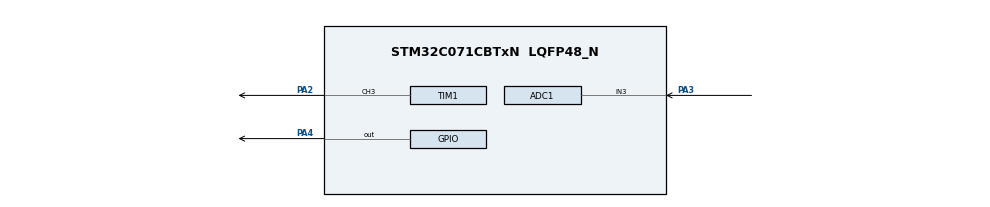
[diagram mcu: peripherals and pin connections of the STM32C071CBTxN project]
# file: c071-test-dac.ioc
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ADC1.DMAContinuousRequests=ENABLE
ADC1.ExternalTrigConv=ADC_EXTERNALTRIG_T1_TRGO2
ADC1.NbrOfConversionFlag=0
ADC1.Resolution=ADC_RESOLUTION_8B
ADC1.SelectedChannel=ADC_CHANNEL_3
ADC1.TriggerFrequencyMode=ADC_TRIGGER_FREQ_HIGH
ADC1.master=1
Dma.ADC1.0.Direction=DMA_PERIPH_TO_MEMORY
Dma.ADC1.0.EventEnable=DISABLE
Dma.ADC1.0.Instance=DMA1_Channel1
Dma.ADC1.0.MemDataAlignment=DMA_MDATAALIGN_BYTE
Dma.ADC1.0.MemInc=DMA_MINC_DISABLE
Dma.ADC1.0.Mode=DMA_CIRCULAR
Dma.ADC1.0.PeriphDataAlignment=DMA_PDATAALIGN_BYTE
Dma.ADC1.0.PeriphInc=DMA_PINC_DISABLE
Dma.ADC1.0.Polarity=HAL_DMAMUX_REQ_GEN_RISING
Dma.ADC1.0.Priority=DMA_PRIORITY_LOW
Dma.ADC1.0.RequestNumber=1
Dma.ADC1.0.SignalID=NONE
Dma.ADC1.0.SyncEnable=DISABLE
Dma.ADC1.0.SyncPolarity=HAL_DMAMUX_SYNC_NO_EVENT
Dma.ADC1.0.SyncRequestNumber=1
Dma.ADC1.0.SyncSignalID=NONE
Dma.Request0=ADC1
Dma.Request1=TIM1_CH3
Dma.TIM1_CH3.1.Direction=DMA_MEMORY_TO_PERIPH
Dma.TIM1_CH3.1.EventEnable=DISABLE
Dma.TIM1_CH3.1.Instance=DMA1_Channel2
Dma.TIM1_CH3.1.MemDataAlignment=DMA_MDATAALIGN_HALFWORD
Dma.TIM1_CH3.1.MemInc=DMA_MINC_DISABLE
Dma.TIM1_CH3.1.Mode=DMA_CIRCULAR
Dma.TIM1_CH3.1.PeriphDataAlignment=DMA_PDATAALIGN_HALFWORD
Dma.TIM1_CH3.1.PeriphInc=DMA_PINC_DISABLE
Dma.TIM1_CH3.1.Polarity=HAL_DMAMUX_REQ_GEN_RISING
Dma.TIM1_CH3.1.Priority=DMA_PRIORITY_MEDIUM
Dma.TIM1_CH3.1.RequestNumber=1
Dma.TIM1_CH3.1.SignalID=NONE
Dma.TIM1_CH3.1.SyncEnable=DISABLE
Dma.TIM1_CH3.1.SyncPolarity=HAL_DMAMUX_SYNC_NO_EVENT
Dma.TIM1_CH3.1.SyncRequestNumber=1
Dma.TIM1_CH3.1.SyncSignalID=NONE
Mcu.Family=STM32C0
Mcu.Name=STM32C071CBTxN
Mcu.Package=LQFP48_N
NVIC.DMA1_Channel2_3_IRQn=true\:0\:0\:false\:false\:true\:false\:true\:true
NVIC.TIM17_IRQn=true\:0\:0\:false\:false\:true\:true\:true\:true
PA13.Mode=Serial_Wire
PA13.Signal=DEBUG_SWDIO
PA14-BOOT0.Mode=Serial_Wire
PA14-BOOT0.Signal=DEBUG_SWCLK
PA2.Signal=S_TIM1_CH3
PA3.Mode=IN3
PA3.Signal=ADC1_IN3
PA4.Signal=GPIO_Output
ProjectManager.HeapSize=0x200
ProjectManager.StackSize=0x400
ProjectManager.TargetToolchain=STM32CubeIDE
RCC.ADCFreq_Value=48000000
RCC.AHBFreq_Value=48000000
RCC.CortexFreq_Value=48000000
RCC.EXTERNAL_CLOCK_VALUE=12288000
RCC.HCLKFreq_Value=48000000
RCC.HSE_VALUE=8000000
RCC.HSI48_VALUE=48000000
RCC.HSISYSCLKDivider=RCC_HSI_DIV1
RCC.HSI_VALUE=48000000
RCC.LSE_VALUE=32768
RCC.SYSCLKFreq_VALUE=48000000
SH.S_TIM1_CH3.0=TIM1_CH3,PWM Generation3 CH3
TIM1.Channel-PWM\ Generation3\ CH3=TIM_CHANNEL_3
TIM1.OC3Preload_PWM=ENABLE
TIM1.OCMode_PWM-PWM\ Generation3\ CH3=TIM_OCMODE_PWM1
TIM1.Period=255
TIM1.TIM_MasterOutputTrigger=TIM_TRGO_RESET
TIM1.TIM_MasterOutputTrigger2=TIM_TRGO2_UPDATE
TIM1.TIM_MasterSlaveMode=TIM_MASTERSLAVEMODE_ENABLE
TIM17.Period=1000
TIM17.Prescaler=47
VP_TIM17_VS_ClockSourceINT.Mode=Enable_Timer
VP_TIM1_VS_ClockSourceINT.Mode=Internal
board=custom

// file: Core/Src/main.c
/* USER CODE BEGIN Header */
/**
  ******************************************************************************
  * @file           : main.c
  * @brief          : Main program body
  ******************************************************************************
  * @attention
  *
  * Copyright (c) 2026 STMicroelectronics.
  * All rights reserved.
  *
  * This software is licensed under terms that can be found in the LICENSE file
  * in the root directory of this software component.
  * If no LICENSE file comes with this software, it is provided AS-IS.
  *
  ******************************************************************************
  */
/* USER CODE END Header */
#include "main.h"

ADC_HandleTypeDef hadc1;
DMA_HandleTypeDef hdma_adc1;

TIM_HandleTypeDef htim1;
TIM_HandleTypeDef htim17;
DMA_HandleTypeDef hdma_tim1_ch3;

/* USER CODE BEGIN PV */

uint16_t value = 0;
uint8_t maxSteps = 255;
uint8_t numSteps = 250;
float maxVoltage = 3.0;
float targetVoltage = 3.0;
uint8_t maxValue = 255;
uint8_t step = 1;
uint8_t endDelay = 1; //steps of delay

uint8_t adcValue = 0;
uint8_t adcValues[12][2];

/* USER CODE END PV */

void SystemClock_Config(void);
static void MX_GPIO_Init(void);
static void MX_DMA_Init(void);
static void MX_TIM1_Init(void);
static void MX_ADC1_Init(void);
static void MX_TIM17_Init(void);

int main(void)
{

  /* MCU Configuration--------------------------------------------------------*/

  /* Reset of all peripherals, Initializes the Flash interface and the Systick. */
  HAL_Init();

  /* Configure the system clock */
  SystemClock_Config();

  /* Initialize all configured peripherals */
  MX_GPIO_Init();
  MX_DMA_Init();
  MX_TIM1_Init();
  MX_ADC1_Init();
  MX_TIM17_Init();
  /* USER CODE BEGIN 2 */
  // Run this ONCE during initialization, before starting the ADC
  if (HAL_ADCEx_Calibration_Start(&hadc1) != HAL_OK) {
      // Calibration Error Handling
      Error_Handler();
  }

  //HAL_ADC_Start_DMA(&hadc1, (uint32_t *)&adcValue, 1);
  //HAL_TIM_PWM_Start_DMA(&htim1, TIM_CHANNEL_3, (uint32_t *)&adcValue, 1);

  HAL_TIM_Base_Start_IT(&htim17);
  HAL_TIM_PWM_Start(&htim1, TIM_CHANNEL_3);

  //HAL_TIM_PWM_Start(&htim1, TIM_CHANNEL_3);
  //HAL_ADC_Start_DMA(&hadc1, (uint32_t *)&(htim1.Instance->CCR3), 1);

  // var init test measurments
  targetVoltage = 1;
  numSteps = 10;

  /* USER CODE END 2 */

  /* Infinite loop */
  /* USER CODE BEGIN WHILE */
  while (1)
  {
	  maxValue = targetVoltage/maxVoltage * maxSteps;
	  step = maxValue / numSteps;
    /* USER CODE END WHILE */

  }
}

void SystemClock_Config(void)
{
  RCC_OscInitTypeDef RCC_OscInitStruct = {0};
  RCC_ClkInitTypeDef RCC_ClkInitStruct = {0};

  __HAL_FLASH_SET_LATENCY(FLASH_LATENCY_1);

  /** Initializes the RCC Oscillators according to the specified parameters
  * in the RCC_OscInitTypeDef structure.
  */
  RCC_OscInitStruct.OscillatorType = RCC_OSCILLATORTYPE_HSI;
  RCC_OscInitStruct.HSIState = RCC_HSI_ON;
  RCC_OscInitStruct.HSIDiv = RCC_HSI_DIV1;
  RCC_OscInitStruct.HSICalibrationValue = RCC_HSICALIBRATION_DEFAULT;
  if (HAL_RCC_OscConfig(&RCC_OscInitStruct) != HAL_OK)
  {
    Error_Handler();
  }

  /** Initializes the CPU, AHB and APB buses clocks
  */
  RCC_ClkInitStruct.ClockType = RCC_CLOCKTYPE_HCLK|RCC_CLOCKTYPE_SYSCLK
                              |RCC_CLOCKTYPE_PCLK1;
  RCC_ClkInitStruct.SYSCLKSource = RCC_SYSCLKSOURCE_HSI;
  RCC_ClkInitStruct.SYSCLKDivider = RCC_SYSCLK_DIV1;
  RCC_ClkInitStruct.AHBCLKDivider = RCC_HCLK_DIV1;
  RCC_ClkInitStruct.APB1CLKDivider = RCC_APB1_DIV1;

  if (HAL_RCC_ClockConfig(&RCC_ClkInitStruct, FLASH_LATENCY_1) != HAL_OK)
  {
    Error_Handler();
  }
}

static void MX_ADC1_Init(void)
{

  ADC_ChannelConfTypeDef sConfig = {0};

  /** Configure the global features of the ADC (Clock, Resolution, Data Alignment and number of conversion)
  */
  hadc1.Instance = ADC1;
  hadc1.Init.ClockPrescaler = ADC_CLOCK_SYNC_PCLK_DIV2;
  hadc1.Init.Resolution = ADC_RESOLUTION_8B;
  hadc1.Init.DataAlign = ADC_DATAALIGN_RIGHT;
  hadc1.Init.ScanConvMode = ADC_SCAN_SEQ_FIXED;
  hadc1.Init.EOCSelection = ADC_EOC_SINGLE_CONV;
  hadc1.Init.LowPowerAutoWait = DISABLE;
  hadc1.Init.LowPowerAutoPowerOff = DISABLE;
  hadc1.Init.ContinuousConvMode = DISABLE;
  hadc1.Init.NbrOfConversion = 1;
  hadc1.Init.DiscontinuousConvMode = DISABLE;
  hadc1.Init.ExternalTrigConv = ADC_EXTERNALTRIG_T1_TRGO2;
  hadc1.Init.ExternalTrigConvEdge = ADC_EXTERNALTRIGCONVEDGE_RISING;
  hadc1.Init.DMAContinuousRequests = ENABLE;
  hadc1.Init.Overrun = ADC_OVR_DATA_PRESERVED;
  hadc1.Init.SamplingTimeCommon1 = ADC_SAMPLETIME_1CYCLE_5;
  hadc1.Init.OversamplingMode = DISABLE;
  hadc1.Init.TriggerFrequencyMode = ADC_TRIGGER_FREQ_HIGH;
  if (HAL_ADC_Init(&hadc1) != HAL_OK)
  {
    Error_Handler();
  }

  /** Configure Regular Channel
  */
  sConfig.Channel = ADC_CHANNEL_3;
  sConfig.Rank = ADC_RANK_CHANNEL_NUMBER;
  if (HAL_ADC_ConfigChannel(&hadc1, &sConfig) != HAL_OK)
  {
    Error_Handler();
  }

}

static void MX_TIM1_Init(void)
{

  TIM_ClockConfigTypeDef sClockSourceConfig = {0};
  TIM_MasterConfigTypeDef sMasterConfig = {0};
  TIM_OC_InitTypeDef sConfigOC = {0};
  TIM_BreakDeadTimeConfigTypeDef sBreakDeadTimeConfig = {0};

  htim1.Instance = TIM1;
  htim1.Init.Prescaler = 0;
  htim1.Init.CounterMode = TIM_COUNTERMODE_UP;
  htim1.Init.Period = 255;
  htim1.Init.ClockDivision = TIM_CLOCKDIVISION_DIV1;
  htim1.Init.RepetitionCounter = 0;
  htim1.Init.AutoReloadPreload = TIM_AUTORELOAD_PRELOAD_DISABLE;
  if (HAL_TIM_Base_Init(&htim1) != HAL_OK)
  {
    Error_Handler();
  }
  sClockSourceConfig.ClockSource = TIM_CLOCKSOURCE_INTERNAL;
  if (HAL_TIM_ConfigClockSource(&htim1, &sClockSourceConfig) != HAL_OK)
  {
    Error_Handler();
  }
  if (HAL_TIM_PWM_Init(&htim1) != HAL_OK)
  {
    Error_Handler();
  }
  sMasterConfig.MasterOutputTrigger = TIM_TRGO_RESET;
  sMasterConfig.MasterOutputTrigger2 = TIM_TRGO2_UPDATE;
  sMasterConfig.MasterSlaveMode = TIM_MASTERSLAVEMODE_ENABLE;
  if (HAL_TIMEx_MasterConfigSynchronization(&htim1, &sMasterConfig) != HAL_OK)
  {
    Error_Handler();
  }
  sConfigOC.OCMode = TIM_OCMODE_PWM1;
  sConfigOC.Pulse = 0;
  sConfigOC.OCPolarity = TIM_OCPOLARITY_HIGH;
  sConfigOC.OCNPolarity = TIM_OCNPOLARITY_HIGH;
  sConfigOC.OCFastMode = TIM_OCFAST_DISABLE;
  sConfigOC.OCIdleState = TIM_OCIDLESTATE_RESET;
  sConfigOC.OCNIdleState = TIM_OCNIDLESTATE_RESET;
  if (HAL_TIM_PWM_ConfigChannel(&htim1, &sConfigOC, TIM_CHANNEL_3) != HAL_OK)
  {
    Error_Handler();
  }
  sBreakDeadTimeConfig.OffStateRunMode = TIM_OSSR_DISABLE;
  sBreakDeadTimeConfig.OffStateIDLEMode = TIM_OSSI_DISABLE;
  sBreakDeadTimeConfig.LockLevel = TIM_LOCKLEVEL_OFF;
  sBreakDeadTimeConfig.DeadTime = 0;
  sBreakDeadTimeConfig.BreakState = TIM_BREAK_DISABLE;
  sBreakDeadTimeConfig.BreakPolarity = TIM_BREAKPOLARITY_HIGH;
  sBreakDeadTimeConfig.BreakFilter = 0;
  sBreakDeadTimeConfig.BreakAFMode = TIM_BREAK_AFMODE_INPUT;
  sBreakDeadTimeConfig.Break2State = TIM_BREAK2_DISABLE;
  sBreakDeadTimeConfig.Break2Polarity = TIM_BREAK2POLARITY_HIGH;
  sBreakDeadTimeConfig.Break2Filter = 0;
  sBreakDeadTimeConfig.Break2AFMode = TIM_BREAK_AFMODE_INPUT;
  sBreakDeadTimeConfig.AutomaticOutput = TIM_AUTOMATICOUTPUT_DISABLE;
  if (HAL_TIMEx_ConfigBreakDeadTime(&htim1, &sBreakDeadTimeConfig) != HAL_OK)
  {
    Error_Handler();
  }
  HAL_TIM_MspPostInit(&htim1);

}

static void MX_TIM17_Init(void)
{

  htim17.Instance = TIM17;
  htim17.Init.Prescaler = 47;
  htim17.Init.CounterMode = TIM_COUNTERMODE_UP;
  htim17.Init.Period = 1000;
  htim17.Init.ClockDivision = TIM_CLOCKDIVISION_DIV1;
  htim17.Init.RepetitionCounter = 0;
  htim17.Init.AutoReloadPreload = TIM_AUTORELOAD_PRELOAD_DISABLE;
  if (HAL_TIM_Base_Init(&htim17) != HAL_OK)
  {
    Error_Handler();
  }

}

static void MX_DMA_Init(void)
{

  /* DMA controller clock enable */
  __HAL_RCC_DMA1_CLK_ENABLE();

  /* DMA interrupt init */
  /* DMA1_Channel2_3_IRQn interrupt configuration */
  HAL_NVIC_SetPriority(DMA1_Channel2_3_IRQn, 0, 0);
  HAL_NVIC_EnableIRQ(DMA1_Channel2_3_IRQn);

}

static void MX_GPIO_Init(void)
{
  GPIO_InitTypeDef GPIO_InitStruct = {0};

  /* GPIO Ports Clock Enable */
  __HAL_RCC_GPIOA_CLK_ENABLE();

  /*Configure GPIO pin Output Level */
  HAL_GPIO_WritePin(GPIOA, GPIO_PIN_4, GPIO_PIN_RESET);

  /*Configure GPIO pin : PA4 */
  GPIO_InitStruct.Pin = GPIO_PIN_4;
  GPIO_InitStruct.Mode = GPIO_MODE_OUTPUT_PP;
  GPIO_InitStruct.Pull = GPIO_NOPULL;
  GPIO_InitStruct.Speed = GPIO_SPEED_FREQ_LOW;
  HAL_GPIO_Init(GPIOA, &GPIO_InitStruct);

}

/* USER CODE BEGIN 4 */

void HAL_TIM_PeriodElapsedCallback(TIM_HandleTypeDef *htim){

	// compenstation for the capacitor discharge
	if (value > maxValue && value < maxValue+ endDelay*step){
		__HAL_TIM_SET_COMPARE(&htim1, TIM_CHANNEL_3, 0);
		//adcValue = 0;
	}
	else if (value >= maxValue+ endDelay*step)
	{
		value =0;
	}
	else{
		__HAL_TIM_SET_COMPARE(&htim1, TIM_CHANNEL_3, value);
		//adcValue = value;
	}
	value+=step;
	//value = HAL_ADC_GetValue(&hadc1);
}

/* USER CODE END 4 */

void Error_Handler(void)
{
  __disable_irq();
  while (1)
  {
  }
}
